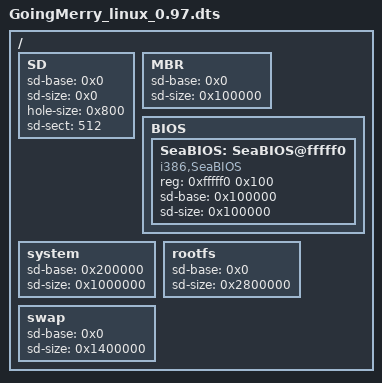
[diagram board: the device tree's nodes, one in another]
/*
 * DTS file for all GoingMerry
 *
 * Copyright 2018 BuddyZhang1 <buddy.zhang@aliyun.com>
 *
 * The code contained herein is licensed under the GNU General Public
 * License. You may obtain a copy of the GNU General Public License
 * Version 2 or later at the following locations:
 *
 * http://www.opensource.org/licenses/gpl-license.html
 * http://www.gnu.org/copyleft/gpl.html
 */
/dts-v1/;

/include/ "i386sx.dtsi"

/ {
	SD {
		sd-base = <0x0>;
		sd-size = <0x0>;
		hole-size = <0x800>;
		sd-sect = <512>;
	};

	MBR {
		sd-base = <0x0>;
		sd-size = <0x100000>;
	};

	BIOS {
		SeaBIOS: SeaBIOS@fffff0 {
			compatible = "i386,SeaBIOS";
			device_type = "BIOS";
			reg = <0xfffff0 0x100>;
			sd-base = <0x100000>;
			sd-size = <0x100000>;
		};
	};

	system {
		sd-base = <0x200000>;
		sd-size = <0x1000000>;
	};

	rootfs {
		sd-base = <0x0>;
		sd-size = <0x2800000>;
	};

	swap {
		sd-base = <0x0>;
		sd-size = <0x1400000>;
	};

};
